VERSION ""
NS_ :

BS_:

BU_:

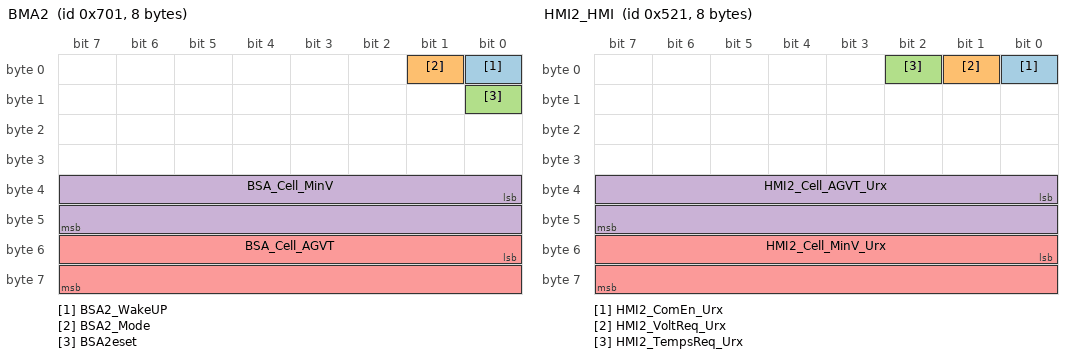
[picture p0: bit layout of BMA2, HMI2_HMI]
BO_ 1793 BMA2: 8 Vector
 SG_ BSA2_WakeUP : 0|1@1+ (1.0,0.0) [0.0|1.0] "" Vector
 SG_ BSA2_Mode : 1|1@1+ (1.0,0.0) [0.0|1.0] "" Vector
 SG_ BSA2eset : 8|1@1+ (1.0,0.0) [0.0|1.0] "" Vector
 SG_ BSA_Cell_MinV : 32|16@1+ (0.001,0.0) [2.8|4.5] "" Vector
 SG_ BSA_Cell_AGVT : 48|16@1- (0.1,0.0) [-40.0|100.0] "" Vector

BO_ 1313 HMI2_HMI: 8 Vector
 SG_ HMI2_ComEn_Urx : 0|1@1+ (1.0,0.0) [0.0|1.0] "" Vector
 SG_ HMI2_VoltReq_Urx : 1|1@1+ (1.0,0.0) [0.0|1.0] "" Vector
 SG_ HMI2_TempsReq_Urx : 2|1@1+ (1.0,0.0) [0.0|1.0] "" Vector
 SG_ HMI2_Cell_AGVT_Urx : 32|16@1- (0.1,0.0) [-40.0|100.0] "" Vector
 SG_ HMI2_Cell_MinV_Urx : 48|16@1+ (0.001,0.0) [2.8|4.5] "" Vector

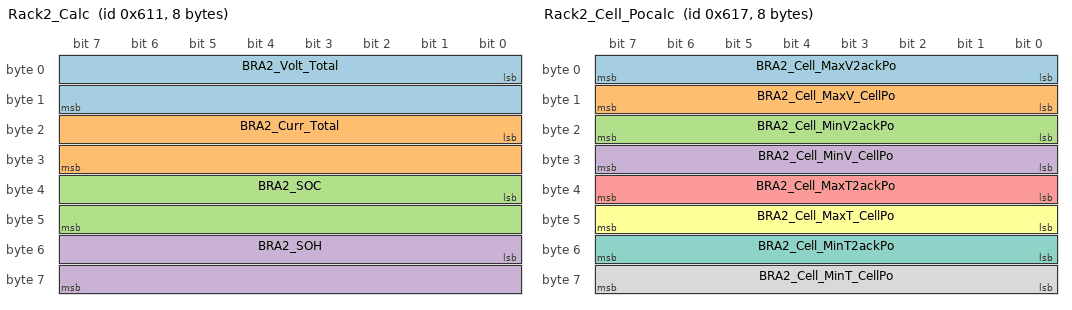
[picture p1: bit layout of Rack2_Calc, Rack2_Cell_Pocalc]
BO_ 1553 Rack2_Calc: 8 Vector
 SG_ BRA2_Volt_Total : 0|16@1+ (0.1,0.0) [400.0|800.0] "" Vector
 SG_ BRA2_Curr_Total : 16|16@1- (0.1,0.0) [-500.0|500.0] "" Vector
 SG_ BRA2_SOC : 32|16@1+ (0.1,0.0) [0.0|120.0] "" Vector
 SG_ BRA2_SOH : 48|16@1+ (0.1,0.0) [0.0|100.0] "" Vector

BO_ 1559 Rack2_Cell_Pocalc: 8 Vector
 SG_ BRA2_Cell_MaxV2ackPo : 0|8@1+ (1.0,0.0) [1.0|4.0] "" Vector
 SG_ BRA2_Cell_MaxV_CellPo : 8|8@1+ (1.0,0.0) [1.0|168.0] "" Vector
 SG_ BRA2_Cell_MinV2ackPo : 16|8@1+ (1.0,0.0) [1.0|4.0] "" Vector
 SG_ BRA2_Cell_MinV_CellPo : 24|8@1+ (1.0,0.0) [1.0|168.0] "" Vector
 SG_ BRA2_Cell_MaxT2ackPo : 32|8@1+ (1.0,0.0) [1.0|4.0] "" Vector
 SG_ BRA2_Cell_MaxT_CellPo : 40|8@1+ (1.0,0.0) [1.0|168.0] "" Vector
 SG_ BRA2_Cell_MinT2ackPo : 48|8@1+ (1.0,0.0) [1.0|4.0] "" Vector
 SG_ BRA2_Cell_MinT_CellPo : 56|8@1+ (1.0,0.0) [1.0|168.0] "" Vector

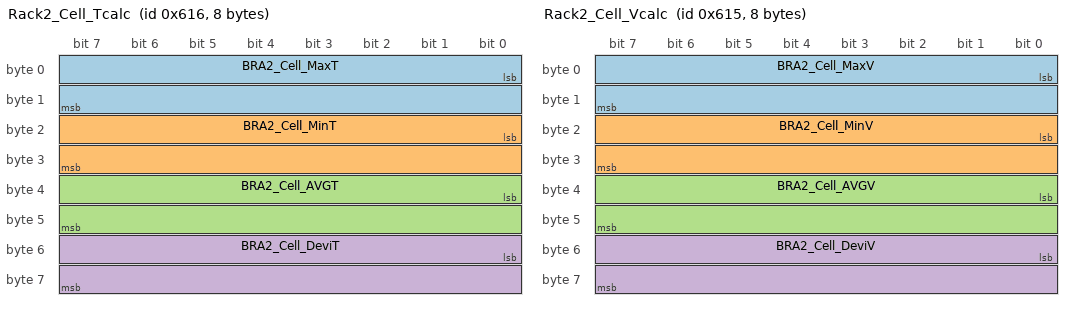
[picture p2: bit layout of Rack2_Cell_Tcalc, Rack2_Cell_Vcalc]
BO_ 1558 Rack2_Cell_Tcalc: 8 Vector
 SG_ BRA2_Cell_MaxT : 0|16@1- (0.1,0.0) [-40.0|100.0] "" Vector
 SG_ BRA2_Cell_MinT : 16|16@1- (0.1,0.0) [-40.0|100.0] "" Vector
 SG_ BRA2_Cell_AVGT : 32|16@1- (0.1,0.0) [-40.0|100.0] "" Vector
 SG_ BRA2_Cell_DeviT : 48|16@1+ (0.1,0.0) [-40.0|100.0] "" Vector

BO_ 1557 Rack2_Cell_Vcalc: 8 Vector
 SG_ BRA2_Cell_MaxV : 0|16@1+ (0.001,0.0) [2.8|4.5] "" Vector
 SG_ BRA2_Cell_MinV : 16|16@1+ (0.001,0.0) [2.8|4.5] "" Vector
 SG_ BRA2_Cell_AVGV : 32|16@1+ (0.001,0.0) [2.8|4.5] "" Vector
 SG_ BRA2_Cell_DeviV : 48|16@1+ (1.0,0.0) [0.0|500.0] "" Vector

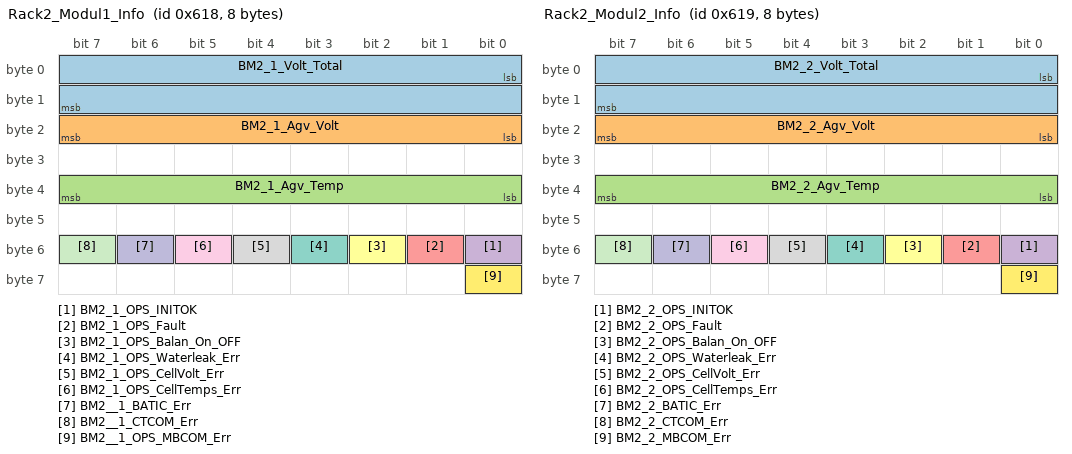
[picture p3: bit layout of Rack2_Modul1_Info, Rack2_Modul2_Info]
BO_ 1560 Rack2_Modul1_Info: 8 Vector
 SG_ BM2_1_Volt_Total : 0|16@1+ (0.1,0.0) [48.0|108.0] "" Vector
 SG_ BM2_1_Agv_Volt : 16|8@1+ (0.001,0.0) [2.8|4.5] "" Vector
 SG_ BM2_1_Agv_Temp : 32|8@1- (0.1,0.0) [-40.0|100.0] "" Vector
 SG_ BM2_1_OPS_INITOK : 48|1@1+ (0.0,0.0) [0.0|1.0] "" Vector
 SG_ BM2_1_OPS_Fault : 49|1@1+ (0.0,0.0) [0.0|1.0] "" Vector
 SG_ BM2_1_OPS_Balan_On_OFF : 50|1@1+ (0.0,0.0) [0.0|1.0] "" Vector
 SG_ BM2_1_OPS_Waterleak_Err : 51|1@1+ (0.0,0.0) [0.0|1.0] "" Vector
 SG_ BM2_1_OPS_CellVolt_Err : 52|1@1+ (0.0,0.0) [0.0|1.0] "" Vector
 SG_ BM2_1_OPS_CellTemps_Err : 53|1@1+ (0.0,0.0) [0.0|1.0] "" Vector
 SG_ BM2__1_BATIC_Err : 54|1@1+ (0.0,0.0) [0.0|1.0] "" Vector
 SG_ BM2__1_CTCOM_Err : 55|1@1+ (0.0,0.0) [0.0|1.0] "" Vector
 SG_ BM2__1_OPS_MBCOM_Err : 56|1@1+ (0.0,0.0) [0.0|1.0] "" Vector

BO_ 1561 Rack2_Modul2_Info: 8 Vector
 SG_ BM2_2_Volt_Total : 0|16@1+ (0.1,0.0) [48.0|108.0] "" Vector
 SG_ BM2_2_Agv_Volt : 16|8@1+ (0.001,0.0) [2.8|4.5] "" Vector
 SG_ BM2_2_Agv_Temp : 32|8@1- (0.1,0.0) [-40.0|100.0] "" Vector
 SG_ BM2_2_OPS_INITOK : 48|1@1+ (0.0,0.0) [0.0|1.0] "" Vector
 SG_ BM2_2_OPS_Fault : 49|1@1+ (0.0,0.0) [0.0|1.0] "" Vector
 SG_ BM2_2_OPS_Balan_On_OFF : 50|1@1+ (0.0,0.0) [0.0|1.0] "" Vector
 SG_ BM2_2_OPS_Waterleak_Err : 51|1@1+ (0.0,0.0) [0.0|1.0] "" Vector
 SG_ BM2_2_OPS_CellVolt_Err : 52|1@1+ (0.0,0.0) [0.0|1.0] "" Vector
 SG_ BM2_2_OPS_CellTemps_Err : 53|1@1+ (0.0,0.0) [0.0|1.0] "" Vector
 SG_ BM2_2_BATIC_Err : 54|1@1+ (0.0,0.0) [0.0|1.0] "" Vector
 SG_ BM2_2_CTCOM_Err : 55|1@1+ (0.0,0.0) [0.0|1.0] "" Vector
 SG_ BM2_2_MBCOM_Err : 56|1@1+ (0.0,0.0) [0.0|1.0] "" Vector

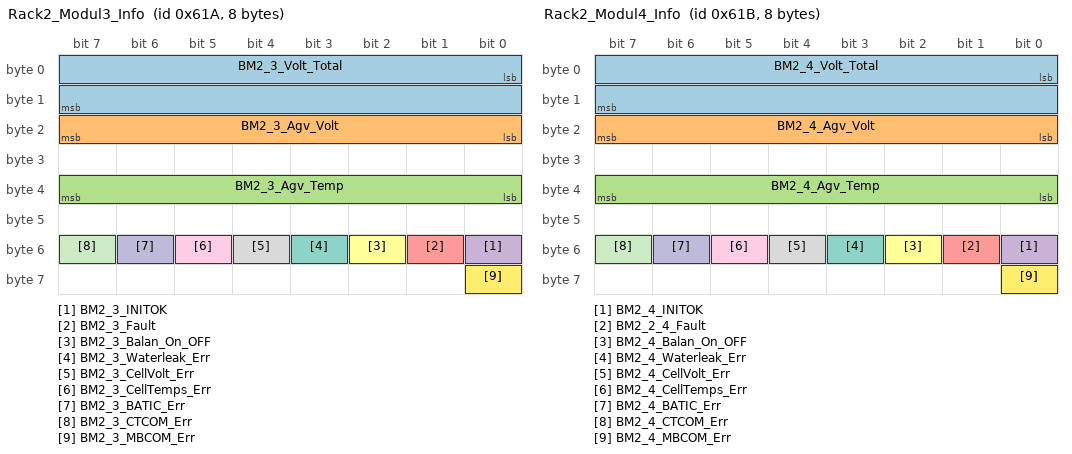
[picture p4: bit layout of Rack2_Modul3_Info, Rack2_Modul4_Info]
BO_ 1562 Rack2_Modul3_Info: 8 Vector
 SG_ BM2_3_Volt_Total : 0|16@1+ (0.1,0.0) [48.0|108.0] "" Vector
 SG_ BM2_3_Agv_Volt : 16|8@1+ (0.001,0.0) [2.8|4.5] "" Vector
 SG_ BM2_3_Agv_Temp : 32|8@1- (0.1,0.0) [-40.0|100.0] "" Vector
 SG_ BM2_3_INITOK : 48|1@1+ (0.0,0.0) [0.0|1.0] "" Vector
 SG_ BM2_3_Fault : 49|1@1+ (0.0,0.0) [0.0|1.0] "" Vector
 SG_ BM2_3_Balan_On_OFF : 50|1@1+ (0.0,0.0) [0.0|1.0] "" Vector
 SG_ BM2_3_Waterleak_Err : 51|1@1+ (0.0,0.0) [0.0|1.0] "" Vector
 SG_ BM2_3_CellVolt_Err : 52|1@1+ (0.0,0.0) [0.0|1.0] "" Vector
 SG_ BM2_3_CellTemps_Err : 53|1@1+ (0.0,0.0) [0.0|1.0] "" Vector
 SG_ BM2_3_BATIC_Err : 54|1@1+ (0.0,0.0) [0.0|1.0] "" Vector
 SG_ BM2_3_CTCOM_Err : 55|1@1+ (0.0,0.0) [0.0|1.0] "" Vector
 SG_ BM2_3_MBCOM_Err : 56|1@1+ (0.0,0.0) [0.0|1.0] "" Vector

BO_ 1563 Rack2_Modul4_Info: 8 Vector
 SG_ BM2_4_Volt_Total : 0|16@1+ (0.1,0.0) [48.0|108.0] "" Vector
 SG_ BM2_4_Agv_Volt : 16|8@1+ (0.001,0.0) [2.8|4.5] "" Vector
 SG_ BM2_4_Agv_Temp : 32|8@1- (0.1,0.0) [-40.0|100.0] "" Vector
 SG_ BM2_4_INITOK : 48|1@1+ (0.0,0.0) [0.0|1.0] "" Vector
 SG_ BM2_2_4_Fault : 49|1@1+ (0.0,0.0) [0.0|1.0] "" Vector
 SG_ BM2_4_Balan_On_OFF : 50|1@1+ (0.0,0.0) [0.0|1.0] "" Vector
 SG_ BM2_4_Waterleak_Err : 51|1@1+ (0.0,0.0) [0.0|1.0] "" Vector
 SG_ BM2_4_CellVolt_Err : 52|1@1+ (0.0,0.0) [0.0|1.0] "" Vector
 SG_ BM2_4_CellTemps_Err : 53|1@1+ (0.0,0.0) [0.0|1.0] "" Vector
 SG_ BM2_4_BATIC_Err : 54|1@1+ (0.0,0.0) [0.0|1.0] "" Vector
 SG_ BM2_4_CTCOM_Err : 55|1@1+ (0.0,0.0) [0.0|1.0] "" Vector
 SG_ BM2_4_MBCOM_Err : 56|1@1+ (0.0,0.0) [0.0|1.0] "" Vector

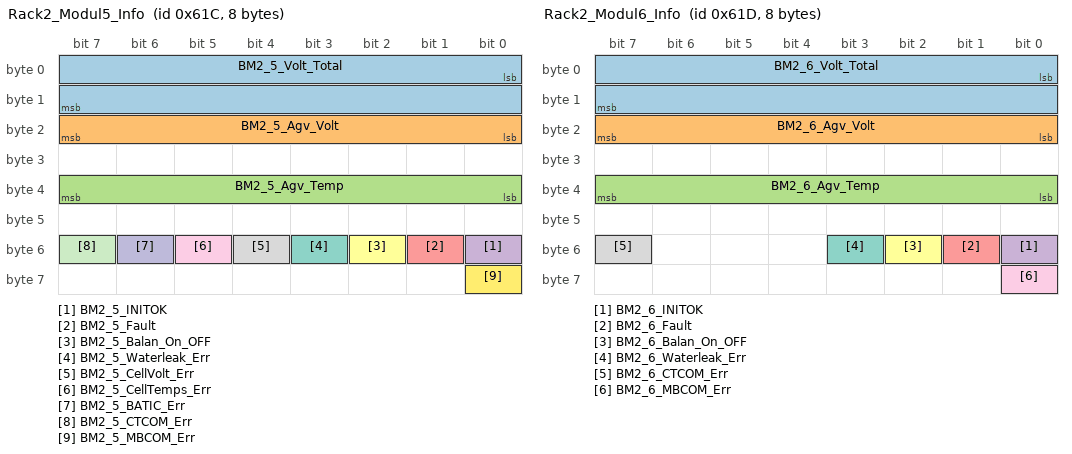
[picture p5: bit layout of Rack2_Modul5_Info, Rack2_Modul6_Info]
BO_ 1564 Rack2_Modul5_Info: 8 Vector
 SG_ BM2_5_Volt_Total : 0|16@1+ (0.1,0.0) [48.0|108.0] "" Vector
 SG_ BM2_5_Agv_Volt : 16|8@1+ (0.001,0.0) [2.8|4.5] "" Vector
 SG_ BM2_5_Agv_Temp : 32|8@1- (0.1,0.0) [-40.0|100.0] "" Vector
 SG_ BM2_5_INITOK : 48|1@1+ (0.0,0.0) [0.0|1.0] "" Vector
 SG_ BM2_5_Fault : 49|1@1+ (0.0,0.0) [0.0|1.0] "" Vector
 SG_ BM2_5_Balan_On_OFF : 50|1@1+ (0.0,0.0) [0.0|1.0] "" Vector
 SG_ BM2_5_Waterleak_Err : 51|1@1+ (0.0,0.0) [0.0|1.0] "" Vector
 SG_ BM2_5_CellVolt_Err : 52|1@1+ (0.0,0.0) [0.0|1.0] "" Vector
 SG_ BM2_5_CellTemps_Err : 53|1@1+ (0.0,0.0) [0.0|1.0] "" Vector
 SG_ BM2_5_BATIC_Err : 54|1@1+ (0.0,0.0) [0.0|1.0] "" Vector
 SG_ BM2_5_CTCOM_Err : 55|1@1+ (0.0,0.0) [0.0|1.0] "" Vector
 SG_ BM2_5_MBCOM_Err : 56|1@1+ (0.0,0.0) [0.0|1.0] "" Vector

BO_ 1565 Rack2_Modul6_Info: 8 Vector
 SG_ BM2_6_Volt_Total : 0|16@1+ (0.1,0.0) [48.0|108.0] "" Vector
 SG_ BM2_6_Agv_Volt : 16|8@1+ (0.001,0.0) [2.8|4.5] "" Vector
 SG_ BM2_6_Agv_Temp : 32|8@1- (0.1,0.0) [-40.0|100.0] "" Vector
 SG_ BM2_6_INITOK : 48|1@1+ (0.0,0.0) [0.0|1.0] "" Vector
 SG_ BM2_6_Fault : 49|1@1+ (0.0,0.0) [0.0|1.0] "" Vector
 SG_ BM2_6_Balan_On_OFF : 50|1@1+ (0.0,0.0) [0.0|1.0] "" Vector
 SG_ BM2_6_Waterleak_Err : 51|1@1+ (0.0,0.0) [0.0|1.0] "" Vector
 SG_ BM2_6_CTCOM_Err : 55|1@1+ (0.0,0.0) [0.0|1.0] "" Vector
 SG_ BM2_6_MBCOM_Err : 56|1@1+ (0.0,0.0) [0.0|1.0] "" Vector

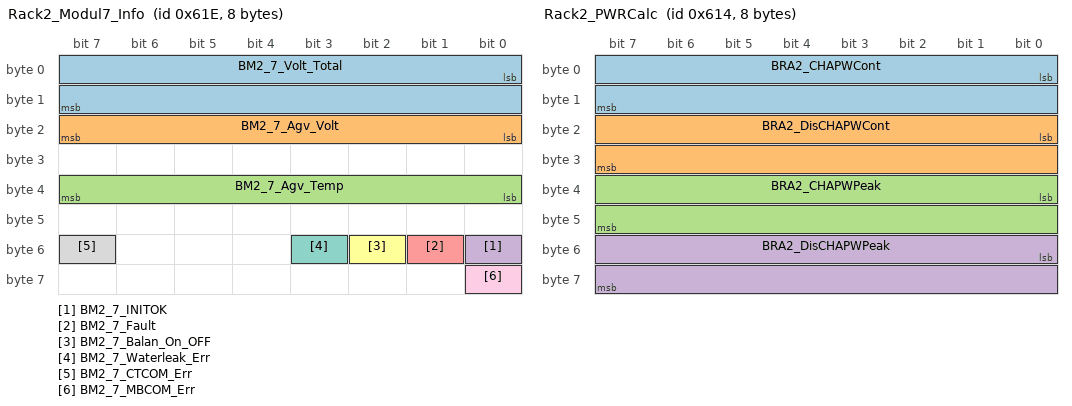
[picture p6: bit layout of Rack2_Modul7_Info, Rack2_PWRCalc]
BO_ 1566 Rack2_Modul7_Info: 8 Vector
 SG_ BM2_7_Volt_Total : 0|16@1+ (0.1,0.0) [48.0|108.0] "" Vector
 SG_ BM2_7_Agv_Volt : 16|8@1+ (0.001,0.0) [2.8|4.5] "" Vector
 SG_ BM2_7_Agv_Temp : 32|8@1- (0.1,0.0) [-40.0|100.0] "" Vector
 SG_ BM2_7_INITOK : 48|1@1+ (0.0,0.0) [0.0|1.0] "" Vector
 SG_ BM2_7_Fault : 49|1@1+ (0.0,0.0) [0.0|1.0] "" Vector
 SG_ BM2_7_Balan_On_OFF : 50|1@1+ (0.0,0.0) [0.0|1.0] "" Vector
 SG_ BM2_7_Waterleak_Err : 51|1@1+ (0.0,0.0) [0.0|1.0] "" Vector
 SG_ BM2_7_CTCOM_Err : 55|1@1+ (0.0,0.0) [0.0|1.0] "" Vector
 SG_ BM2_7_MBCOM_Err : 56|1@1+ (0.0,0.0) [0.0|1.0] "" Vector

BO_ 1556 Rack2_PWRCalc: 8 Vector
 SG_ BRA2_CHAPWCont : 0|16@1+ (0.1,0.0) [0.0|43.0] "" Vector
 SG_ BRA2_DisCHAPWCont : 16|16@1+ (0.1,0.0) [0.0|100.0] "" Vector
 SG_ BRA2_CHAPWPeak : 32|16@1+ (0.1,0.0) [0.0|60.0] "" Vector
 SG_ BRA2_DisCHAPWPeak : 48|16@1+ (0.1,0.0) [0.0|200.0] "" Vector

BO_ 1555 Rack2_ProtectState: 8 Vector
 SG_ BRA2_Wn_Dischager_OC : 0|1@1+ (1.0,0.0) [0.0|1.0] "" Vector
 SG_ BRA2_Wn_Chager_OC : 1|1@1+ (1.0,0.0) [0.0|1.0] "" Vector
 SG_ BRA2_Wn_SOC_OV : 2|1@1+ (1.0,0.0) [0.0|1.0] "" Vector
 SG_ BRA2_Wn_SOC_Un : 3|1@1+ (1.0,0.0) [0.0|1.0] "" Vector
 SG_ BRA2_Wn_OV : 4|1@1+ (1.0,0.0) [0.0|1.0] "" Vector
 SG_ BRA2_Wn_UV : 5|1@1+ (1.0,0.0) [0.0|1.0] "" Vector
 SG_ BRA2_Wn_Cell_OV : 6|1@1+ (1.0,0.0) [0.0|1.0] "" Vector
 SG_ BRA2_Wn_Cell_UV : 7|1@1+ (1.0,0.0) [0.0|1.0] "" Vector
 SG_ BRA2_Wn_Cell_UnbalV : 8|1@1+ (1.0,0.0) [0.0|1.0] "" Vector
 SG_ BRA2_Wn_DisCharger_Cell_OT : 9|1@1+ (1.0,0.0) [0.0|1.0] "" Vector
 SG_ BRA2_Wn_Charger_Cell_OT : 10|1@1+ (1.0,0.0) [0.0|1.0] "" Vector
 SG_ BRA2_Wn_DisCharger_Cell_UT : 11|1@1+ (1.0,0.0) [0.0|1.0] "" Vector
 SG_ BRA2_Wn_Charger_Cell_UT : 12|1@1+ (1.0,0.0) [0.0|1.0] "" Vector
 SG_ BRA2_Wn_Cell_UnbalT : 13|1@1+ (1.0,0.0) [0.0|1.0] "" Vector
 SG_ BRA2_Wn_Discharger_UnbaPWR : 14|1@1+ (1.0,0.0) [0.0|1.0] "" Vector
 SG_ BRA2_Wn_Charger_UnbaPWR : 15|1@1+ (1.0,0.0) [0.0|1.0] "" Vector
 SG_ BRA2_FLT_Dischager_OC : 16|1@1+ (1.0,0.0) [0.0|1.0] "" Vector
 SG_ BRA2_FLT_Chager_OC : 17|1@1+ (1.0,0.0) [0.0|1.0] "" Vector
 SG_ BRA2_FLT_SOC_OV : 18|1@1+ (1.0,0.0) [0.0|1.0] "" Vector
 SG_ BRA2_FLT_SOC_Un : 19|1@1+ (1.0,0.0) [0.0|1.0] "" Vector
 SG_ BRA2_FLT_OV : 20|1@1+ (1.0,0.0) [0.0|1.0] "" Vector
 SG_ BRA2_FLT_UV : 21|1@1+ (1.0,0.0) [0.0|1.0] "" Vector
 SG_ BRA2_FLT_Cell_OV : 22|1@1+ (1.0,0.0) [0.0|1.0] "" Vector
 SG_ BRA2_FLT_Cell_UV : 23|1@1+ (1.0,0.0) [0.0|1.0] "" Vector
 SG_ BRA2_FLT_Cell_UnbalV : 24|1@1+ (1.0,0.0) [0.0|1.0] "" Vector
 SG_ BRA2_FLT_DisCharger_Cell_OT : 25|1@1+ (1.0,0.0) [0.0|1.0] "" Vector
 SG_ BRA2_FLT_Charger_Cell_OT : 26|1@1+ (1.0,0.0) [0.0|1.0] "" Vector
 SG_ BRA2_FLT_DisCharger_Cell_UT : 27|1@1+ (1.0,0.0) [0.0|1.0] "" Vector
 SG_ BRA2_FLT_Charger_Cell_UT : 28|1@1+ (1.0,0.0) [0.0|1.0] "" Vector
 SG_ BRA2_FLT_Cell_UnbalT : 29|1@1+ (1.0,0.0) [0.0|1.0] "" Vector
 SG_ BRA2_FLT_Discharger_UnbaPWR : 30|1@1+ (1.0,0.0) [0.0|1.0] "" Vector
 SG_ BRA2_FLT_Charger_UnbaPWR : 31|1@1+ (1.0,0.0) [0.0|1.0] "" Vector
 SG_ BRA2_Prtct_Dischager_OC : 32|1@1+ (1.0,0.0) [0.0|1.0] "" Vector
 SG_ BRA2_Prtct_Chager_OC : 33|1@1+ (1.0,0.0) [0.0|1.0] "" Vector
 SG_ BRA2_Prtct_SOC_OV : 34|1@1+ (1.0,0.0) [0.0|1.0] "" Vector
 SG_ BRA2_Prtct_SOC_Un : 35|1@1+ (1.0,0.0) [0.0|1.0] "" Vector
 SG_ BRA2_Prtct_OV : 36|1@1+ (1.0,0.0) [0.0|1.0] "" Vector
 SG_ BRA2_Prtct_UV : 37|1@1+ (1.0,0.0) [0.0|1.0] "" Vector
 SG_ BRA2_Prtct_Cell_OV : 38|1@1+ (1.0,0.0) [0.0|1.0] "" Vector
 SG_ BRA2_Prtct_Cell_UV : 39|1@1+ (1.0,0.0) [0.0|1.0] "" Vector
 SG_ BRA2_Prtct_Cell_UnbalV : 40|1@1+ (1.0,0.0) [0.0|1.0] "" Vector
 SG_ BRA2_Prtct_DisCharger_Cell_OT : 41|1@1+ (1.0,0.0) [0.0|1.0] "" Vector
 SG_ BRA2_Prtct_Charger_Cell_OT : 42|1@1+ (1.0,0.0) [0.0|1.0] "" Vector
 SG_ BRA2_Prtct_DisCharger_Cell_UT : 43|1@1+ (1.0,0.0) [0.0|1.0] "" Vector
 SG_ BRA2_Prtct_Charger_Cell_UT : 44|1@1+ (1.0,0.0) [0.0|1.0] "" Vector
 SG_ BRA2_Prtct_Cell_UnbalT : 45|1@1+ (1.0,0.0) [0.0|1.0] "" Vector
 SG_ BRA2_Prtct_Discharger_UnbaPWR : 46|1@1+ (1.0,0.0) [0.0|1.0] "" Vector
 SG_ BRA2_Prtct_Charger_UnbaPWR : 47|1@1+ (1.0,0.0) [0.0|1.0] "" Vector
 SG_ BRA2_Prtct2ly_Err : 48|1@1+ (1.0,0.0) [0.0|1.0] "" Vector
 SG_ BRA2_Prtct_IN_COM_Err : 49|1@1+ (1.0,0.0) [0.0|1.0] "" Vector
 SG_ BRA2_Prtct_EX_COM_Err : 50|1@1+ (1.0,0.0) [0.0|1.0] "" Vector
 SG_ BRA2_Prtct_CT_COM_Err : 51|1@1+ (1.0,0.0) [0.0|1.0] "" Vector
 SG_ BRA2_Prtct_Water_Leak_Err : 52|1@1+ (1.0,0.0) [0.0|1.0] "" Vector
 SG_ BRA2_Prtct_EMS_SW_Err : 53|1@1+ (1.0,0.0) [0.0|1.0] "" Vector

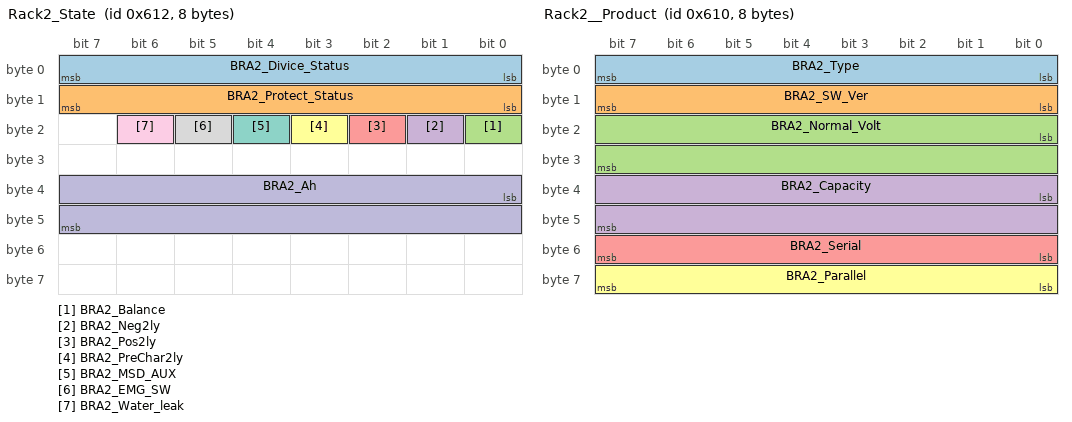
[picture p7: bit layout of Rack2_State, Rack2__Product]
BO_ 1554 Rack2_State: 8 Vector
 SG_ BRA2_Divice_Status : 0|8@1+ (1.0,0.0) [0.0|4.0] "" Vector
 SG_ BRA2_Protect_Status : 8|8@1+ (1.0,0.0) [0.0|4.0] "" Vector
 SG_ BRA2_Balance : 16|1@1+ (1.0,0.0) [0.0|1.0] "" Vector
 SG_ BRA2_Neg2ly : 17|1@1+ (1.0,0.0) [0.0|1.0] "" Vector
 SG_ BRA2_Pos2ly : 18|1@1+ (1.0,0.0) [0.0|1.0] "" Vector
 SG_ BRA2_PreChar2ly : 19|1@1+ (1.0,0.0) [0.0|1.0] "" Vector
 SG_ BRA2_MSD_AUX : 20|1@1+ (1.0,0.0) [0.0|1.0] "" Vector
 SG_ BRA2_EMG_SW : 21|1@1+ (1.0,0.0) [0.0|1.0] "" Vector
 SG_ BRA2_Water_leak : 22|1@1+ (1.0,0.0) [0.0|1.0] "" Vector
 SG_ BRA2_Ah : 32|16@1- (1.0,0.0) [-100.0|-100.0] "" Vector

BO_ 1312 Rack2_Unit: 8 Vector
 SG_ BRA2_Status_Urx : 3|0@1+ (1.0,0.0) [0.0|1.0] "" Vector
 SG_ BRA2_ComEn_Urx : 8|1@1+ (1.0,0.0) [0.0|1.0] "" Vector
 SG_ BRA22eset_Urx : 9|1@1+ (1.0,0.0) [0.0|1.0] "" Vector
 SG_ BRA2_Cell_AGVT_Urx : 32|16@1- (0.1,0.0) [-40.0|100.0] "" Vector
 SG_ BRA2_Cell_MinV_Urx : 48|16@1+ (0.001,0.0) [2.8|4.5] "" Vector

BO_ 1552 Rack2__Product: 8 Vector
 SG_ BRA2_Type : 0|8@1+ (1.0,0.0) [0.0|10.0] "" Vector
 SG_ BRA2_SW_Ver : 8|8@1+ (0.1,0.0) [1.0|2.55] "" Vector
 SG_ BRA2_Normal_Volt : 16|16@1+ (0.1,0.0) [400.0|800.0] "" Vector
 SG_ BRA2_Capacity : 32|16@1+ (0.1,0.0) [30.0|500.0] "" Vector
 SG_ BRA2_Serial : 48|8@1+ (1.0,0.0) [0.0|200.0] "" Vector
 SG_ BRA2_Parallel : 56|8@1+ (1.0,0.0) [0.0|10.0] "" Vector
